VERSION ""

NS_ :

BS_:

BU_: TPMS_ECU

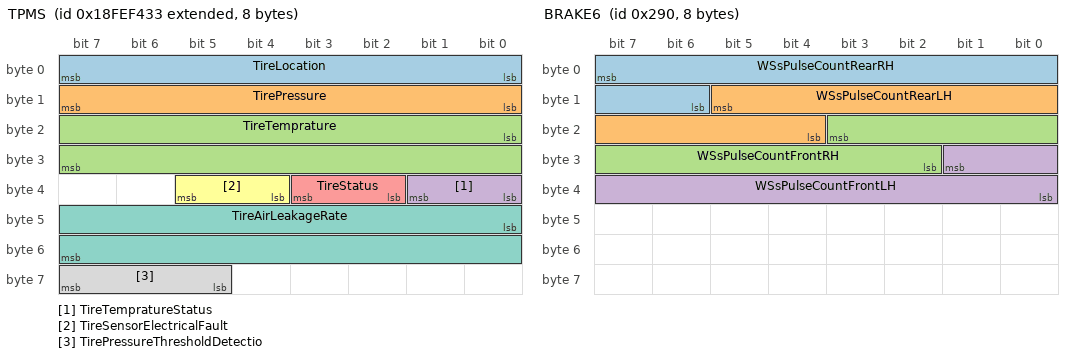
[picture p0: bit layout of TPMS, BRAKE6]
BO_ 2566845491 TPMS: 8 TPMS_ECU
 SG_ TireLocation : 0|8@1+ (1,0) [0|17] "" Vector__XXX
 SG_ TirePressure : 8|8@1+ (4,0) [0|1020] "kPa" Vector__XXX
 SG_ TireTemprature : 16|16@1+ (0.03125,-273) [-273|1735] "degC" Vector__XXX
 SG_ TireTempratureStatus : 32|2@1+ (1,0) [0|3] "" Vector__XXX
 SG_ TireStatus : 34|2@1+ (1,0) [0|3] "" Vector__XXX
 SG_ TireSensorElectricalFault : 36|2@1+ (1,0) [0|3] "" Vector__XXX
 SG_ TireAirLeakageRate : 40|16@1+ (1,0) [0|65535] "" Vector__XXX
 SG_ TirePressureThresholdDetectio : 61|3@1+ (1,0) [0|7] "" Vector__XXX

BO_ 374 BRAKE5: 8 Vector__XXX
 SG_ VehSpdABS : 39|12@0+ (0.03125,0) [0|127.96875] "m/s"  TPMS_ECU
 SG_ VehSpdABsStatus : 43|2@0+ (1,0) [0|3] ""  TPMS_ECU

BO_ 2164195584 AmbientAirTemperature: 8 Vector__XXX
 SG_ AmbientAirTemperature : 0|8@1+ (1,-40) [-40|210] "degC"  TPMS_ECU

BO_ 2164195840 Gearinformation: 8 Vector__XXX
 SG_ TCU_GearShiftPosition : 0|4@1+ (1,0) [0|15] ""  TPMS_ECU

BO_ 656 BRAKE6: 8 Vector__XXX
 SG_ WSsPulseCountRearRH : 7|10@0+ (1,0) [0|1023] ""  TPMS_ECU
 SG_ WSsPulseCountRearLH : 13|10@0+ (1,0) [0|1023] ""  TPMS_ECU
 SG_ WSsPulseCountFrontRH : 19|10@0+ (1,0) [0|1023] ""  TPMS_ECU
 SG_ WSsPulseCountFrontLH : 25|10@0+ (1,0) [0|1023] ""  TPMS_ECU

BO_ 2164196352 IGNsignal: 8 Vector__XXX
 SG_ IGNsingal : 0|2@1+ (1,0) [0|3] ""  TPMS_ECU

BO_ 2164196608 TotalOdometer: 8 Vector__XXX
 SG_ TotalOdometer : 0|32@1+ (0.1,0) [0|999999] "km"  TPMS_ECU

CM_ "$File: //depot/auto/dbc/Third_party_components/BHSens/Arrival_VAN_TPMS/0.0.3.0/Arrival_VAN_TPMS.dbc $
$Change: 216206 $
$DateTime: 2024/08/26 10:15:09 $
$Revision: #1 $";
CM_ SG_ 2566845491 TireLocation "Tire Location";
CM_ SG_ 2566845491 TirePressure "Tire Pressure";
CM_ SG_ 2566845491 TireTemprature "Tire Temprature";
CM_ SG_ 2566845491 TireTempratureStatus "Tire Temprature Status";
CM_ SG_ 2566845491 TireStatus "Tire Status";
CM_ SG_ 2566845491 TireSensorElectricalFault "Tire Sensor Electrical Fault";
CM_ SG_ 374 VehSpdABS "vehicle speed signal calculated by ABS and ESP ECU and will be given to IC";
CM_ SG_ 374 VehSpdABsStatus "status information of VehSpdABs";
CM_ SG_ 2164195584 AmbientAirTemperature "AmbientAirTemperature";
CM_ SG_ 2164195840 TCU_GearShiftPosition "TCU_GearShiftPosition";
CM_ BO_ 656 "Geartoothpulsesignalofthe4";
CM_ BO_ 2164196352 "IGN signal";
CM_ SG_ 2164196608 TotalOdometer "Total Odometer";
BA_DEF_  "DBName" STRING ;
BA_DEF_  "BusType" STRING ;
BA_DEF_ BO_  "GenMsgCycleTime" INT 0 3600000;
BA_DEF_ SG_  "GenSigStartValue" FLOAT -3.4E+038 3.4E+038;
BA_DEF_DEF_  "DBName" "Arrival_VAN_TPMS";
BA_DEF_DEF_  "BusType" "CAN";
BA_DEF_DEF_  "GenMsgCycleTime" 0;
BA_DEF_DEF_  "GenSigStartValue" 0;
BA_ "GenMsgCycleTime" BO_ 2164195584 100;
BA_ "GenMsgCycleTime" BO_ 2164195840 100;
BA_ "GenMsgCycleTime" BO_ 2164196352 100;
BA_ "GenSigStartValue" SG_ 2566845491 TirePressure 63.75;
BA_ "GenSigStartValue" SG_ 2566845491 TireTemprature 8736;
BA_ "GenSigStartValue" SG_ 2566845491 TireTempratureStatus 3;
BA_ "GenSigStartValue" SG_ 2566845491 TireStatus 3;
BA_ "GenSigStartValue" SG_ 2566845491 TireSensorElectricalFault 3;
BA_ "GenSigStartValue" SG_ 2566845491 TirePressureThresholdDetectio 7;
BA_ "GenSigStartValue" SG_ 2164195584 AmbientAirTemperature 40;
VAL_ 2566845491 TireLocation 0 "left front tire" 1 "right front tire" 16 "left rear tire" 17 "right rear tire" ;
VAL_ 2566845491 TireTempratureStatus 3 "reserved" 2 "reserved" 1 "reserved" 0 "Ok (no fault)" ;
VAL_ 2566845491 TireStatus 3 "Not Supported" 0 "Ok" 1 "Tire leak detected" 2 "Error" ;
VAL_ 2566845491 TireSensorElectricalFault 3 "Not Supported" 2 "Error(lost sensor 10minutes)" 1 "Not Defined" 0 "Ok ( No Fault)" ;
VAL_ 2566845491 TireAirLeakageRate 65535 "NA" ;
VAL_ 2566845491 TirePressureThresholdDetectio 0 "Reserved" 1 "Over pressure" 2 "No warning pressure" 3 "Under pressure" 4 "Reserved" 5 "Not defined" 6 "Error indicator" 7 "Not available" ;
VAL_ 374 VehSpdABsStatus 3 "Reserved for future" 2 "Value is implausible" 0 "Value is correct

" 1 "Reserved for future" ;
VAL_ 2164195840 TCU_GearShiftPosition 0 "P" 5 "D" 6 "N" 7 "R" 8 "M" 15 "Invalid" 1 "L(Reserved)" 2 "2(Reserved)" 3 "3(Reserved)" ;
VAL_ 2164196352 IGNsingal 0 "OFF" 1 "ACC" 2 "ON" 3 "START" ;
